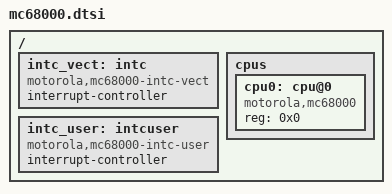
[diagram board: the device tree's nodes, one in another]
// SPDX-License-Identifier: GPL-2.0+
/*
 * Copyright (C) 2024 Daniel Palmer <daniel@thingy.jp>
 */

/ {
	intc_vect: intc {
		compatible = "motorola,mc68000-intc-vect";
		#interrupt-cells = <1>;
		interrupt-controller;
		status = "okay";
	};

	intc_user: intcuser {
		compatible = "motorola,mc68000-intc-user";
		#interrupt-cells = <1>;
		interrupt-controller;
		status = "okay";
	};

	cpus: cpus {
		#address-cells = <1>;
		#size-cells = <0>;
		cpu0: cpu@0 {
			compatible = "motorola,mc68000";
			device_type = "cpu";
			reg = <0x0>;
		};
	};
};
